AUTOSAR XML (schema 00048)
package /ComponentTypes
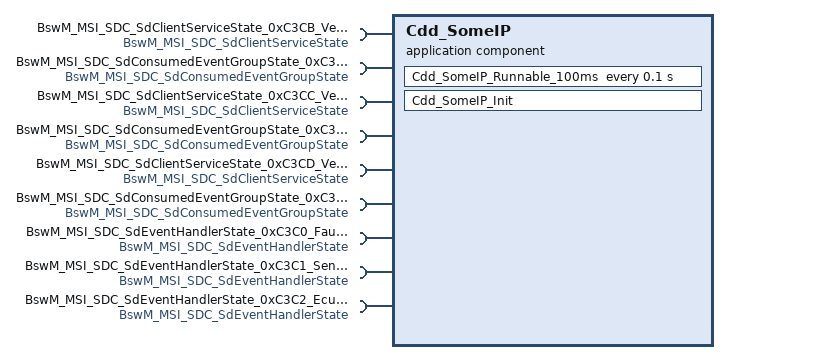
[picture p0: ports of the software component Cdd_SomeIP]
  application sw component type Cdd_SomeIP
    9 x require port:
      BswM_MSI_SDC_SdClientServiceState_0xC3CB_VechicleSpeed: mode-switch-receiver-com-spec=BswM_MDGP_SDC_SdClientServiceState, required-interface=BswM_MSI_SDC_SdClientServiceState
      BswM_MSI_SDC_SdConsumedEventGroupState_0xC3CB_VechicleSpeed: mode-switch-receiver-com-spec=BswM_MDGP_SDC_SdConsumedEventGroupState, required-interface=BswM_MSI_SDC_SdConsumedEventGroupState
      BswM_MSI_SDC_SdClientServiceState_0xC3CC_VechicleStatus: mode-switch-receiver-com-spec=BswM_MDGP_SDC_SdClientServiceState, required-interface=BswM_MSI_SDC_SdClientServiceState
      BswM_MSI_SDC_SdConsumedEventGroupState_0xC3CC_VechicleStatus: mode-switch-receiver-com-spec=BswM_MDGP_SDC_SdConsumedEventGroupState, required-interface=BswM_MSI_SDC_SdConsumedEventGroupState
      BswM_MSI_SDC_SdClientServiceState_0xC3CD_VechicleInfo: mode-switch-receiver-com-spec=BswM_MDGP_SDC_SdClientServiceState, required-interface=BswM_MSI_SDC_SdClientServiceState
      BswM_MSI_SDC_SdConsumedEventGroupState_0xC3CD_VechicleInfo: mode-switch-receiver-com-spec=BswM_MDGP_SDC_SdConsumedEventGroupState, required-interface=BswM_MSI_SDC_SdConsumedEventGroupState
      BswM_MSI_SDC_SdEventHandlerState_0xC3C0_FaultInfo: mode-switch-receiver-com-spec=BswM_MDGP_SDC_SdEventHandlerState, required-interface=BswM_MSI_SDC_SdEventHandlerState
      BswM_MSI_SDC_SdEventHandlerState_0xC3C1_SenState: mode-switch-receiver-com-spec=BswM_MDGP_SDC_SdEventHandlerState, required-interface=BswM_MSI_SDC_SdEventHandlerState
      BswM_MSI_SDC_SdEventHandlerState_0xC3C2_EcuState: mode-switch-receiver-com-spec=BswM_MDGP_SDC_SdEventHandlerState, required-interface=BswM_MSI_SDC_SdEventHandlerState
    behavior Cdd_SomeIP_InternalBehavior
      init event Cdd_SomeIP_InitEvent: start-on-event=Cdd_SomeIP_Init
      timing event TMT_Cdd_SomeIP_Runnable_100ms: start-on-event=Cdd_SomeIP_Runnable_100ms, period=0.1
      runnable Cdd_SomeIP_Init
      runnable Cdd_SomeIP_Runnable_100ms
        mode-access-points:
          BswM_MSI_SDC_SdClientServiceState_0xC3CB_VechicleSpeed.BswM_MDGP_SDC_SdClientServiceState
          BswM_MSI_SDC_SdClientServiceState_0xC3CC_VechicleStatus.BswM_MDGP_SDC_SdClientServiceState
          BswM_MSI_SDC_SdClientServiceState_0xC3CD_VechicleInfo.BswM_MDGP_SDC_SdClientServiceState
          BswM_MSI_SDC_SdConsumedEventGroupState_0xC3CB_VechicleSpeed.BswM_MDGP_SDC_SdConsumedEventGroupState
          BswM_MSI_SDC_SdConsumedEventGroupState_0xC3CC_VechicleStatus.BswM_MDGP_SDC_SdConsumedEventGroupState
          BswM_MSI_SDC_SdConsumedEventGroupState_0xC3CD_VechicleInfo.BswM_MDGP_SDC_SdConsumedEventGroupState
          BswM_MSI_SDC_SdEventHandlerState_0xC3C0_FaultInfo.BswM_MDGP_SDC_SdEventHandlerState
          BswM_MSI_SDC_SdEventHandlerState_0xC3C1_SenState.BswM_MDGP_SDC_SdEventHandlerState
          BswM_MSI_SDC_SdEventHandlerState_0xC3C2_EcuState.BswM_MDGP_SDC_SdEventHandlerState
  swc implementation Cdd_SomeIP_Implementation: behavior=Cdd_SomeIP_InternalBehavior
